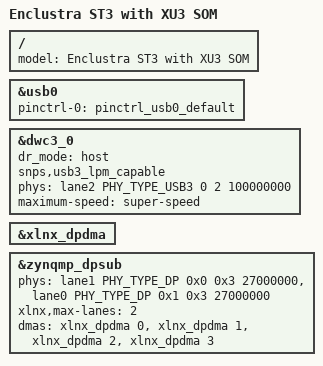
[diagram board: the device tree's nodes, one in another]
/*
 * dts file for Enclustra XU3 SOM
 *
 * (C) Copyright 2018, Xilinx, Inc.
 * (C) Copyright 2019, Enclustra
 *
 * This program is free software; you can redistribute it and/or
 * modify it under the terms of the GNU General Public License as
 * published by the Free Software Foundation; either version 2 of
 * the License, or (at your option) any later version.
 */

#include "zynqmp-enclustra-xu3.dts"

/ {
	model = "Enclustra ST3 with XU3 SOM";
};

&usb0 {
	status = "okay";
	pinctrl-names = "default";
	pinctrl-0 = <&pinctrl_usb0_default>;
};

&dwc3_0 {
	status = "okay";
	dr_mode = "host";
	snps,usb3_lpm_capable;
	phy-names = "usb3-phy";
	phys = <&lane2 PHY_TYPE_USB3 0 2 100000000>;
	maximum-speed = "super-speed";
};

&xlnx_dpdma {
	status = "okay";
};

&zynqmp_dpsub {
	status = "okay";
	phy-names = "dp-phy0", "dp-phy1";
	phys = <&lane1 PHY_TYPE_DP 0x0 0x3 27000000>, <&lane0 PHY_TYPE_DP 0x1 0x3 27000000>;
	xlnx,max-lanes = <2>;
	dma-names = "vid0", "vid1", "vid2", "gfx0";
	dmas = <&xlnx_dpdma 0>, <&xlnx_dpdma 1>, <&xlnx_dpdma 2>, <&xlnx_dpdma 3>;
};
